# HSPLL_367.0 register map
Vendor: Texas Instruments
Peripheral module from a debugger description file (folder msp430).
Registers are 16-bit, read-only, no defined reset value unless marked. A register's access mark holds for its fields unless they carry their own. Offsets are as the file gives them; lines under a group give offsets from that group; [hi:lo] are bit positions; {n}, {i} and the like mark numbered series; 'fields as' and 'values as' point back to an identical list; <NAME> marks a mode.

## HSPLL
0x00 HSPLLIIDX — Interrupt Index Register
  [15:1] IIDX — HSPLL Interrupt Vector Value
    0=No Interrupt pending; 1=Interrupt Source: PLLUNLOCK; Interrupt Priority: Highest; 2=Reserved; Interrupt Priority: Lowest
0x02 HSPLLMIS — Masked Interrupt Status Register.
  [0] PLLUNLOCK — HSPLL Unlock Masked Interrupt Status bit
    0=No interrupt pending; 1=Interrupt pending
0x04 HSPLLRIS — Raw Interrupt Status Register
  [0] PLLUNLOCK — PLL Unlock Raw Interrupt Status bit.
    0=PLL status has not been changed; 1=PLL status has been changed from Lock to Unlock
0x06 HSPLLIMSC rw — Interrupt Mask Register
  [0] PLLUNLOCK — PLL Unlock Interrupt Mask bit.
    0=PLL Unlock Interrupt is disabled; 1=PLL Unlock Interrupt is enabled
0x08 HSPLLICR rw — Interrupt Flag Clear Register.
  [0] PLLUNLOCK — PLL Unlock Interrupt Clear bit.
0x0A HSPLLISR rw — Interrupt Flag Set Register.
  [0] PLLUNLOCK — PLL Unlock Interrupt Set bit.
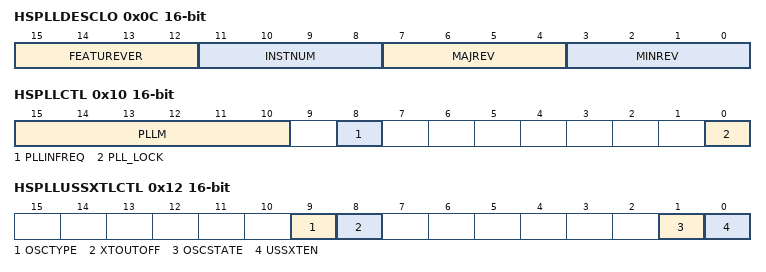
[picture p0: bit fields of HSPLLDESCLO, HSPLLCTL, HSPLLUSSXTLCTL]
0x0C HSPLLDESCLO — HSPLL Descriptor Register L.
  [15:12] FEATUREVER — Feature Set for the module
  [11:8] INSTNUM — Instance Number within the device.
  [7:4] MAJREV — Major Revision
  [3:0] MINREV — Minor Revision
0x0E HSPLLDESCHI access not given — HSPLL Descriptor Register H.
0x10 HSPLLCTL access per field — HSPLL Control Register
  [15:10] PLLM rw — PLL Multiplier
  [8] PLLINFREQ rw — PLL Input Frequency Selection.
    0=Input frequency is equal to 6MHz or lower than 6MHz; 1=Input frequency is higher than 6MHz
  [0] PLL_LOCK ro — PLL Lock Status
    0=PLL is not running or not locked; 1=PLL is locked
0x12 HSPLLUSSXTLCTL access per field — USSXT Control Register
  [9] OSCTYPE rw — Reserved
    0=XTAL (Gating Counter Length: 4096. It is recommended to use this configuration for crystal resonators. Note: the counter counts the oscillator clock, so total time can be calculated as Time = 4096 x 1/Oscillator Clock Frequency.); 1=CERAMIC (Gating Counter Length: 512. It is recommended to use this configuration for ceramic resonators. Note: the counter counts the oscillator clock, so total time can be calculated as Time = 512x 1/Oscillator Clock Frequency.)
  [8] XTOUTOFF rw — USSXT Buffered Output OFF
    0=Enable USSXT buffered output; 1=Disable USSXT buffered output. Default.
  [1] OSCSTATE ro — Oscillator Status Bit.
    0=Oscillator is either not enabled or in the middle of start-up transition; 1=Oscillator has started but is not stable yet. Wait for sufficient time for stabilization.
  [0] USSXTEN rw — USSXT Enable.
    0=Disable USSXT Oscillator; 1=Enable USSXT Oscillator
